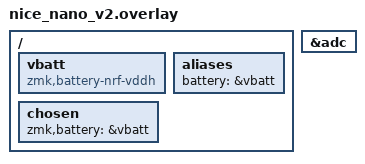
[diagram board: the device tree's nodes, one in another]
/* Enable SAADC and expose a ZMK battery device for nice!nano v2 */

&adc {
    status = "okay";
};

 / {
    vbatt: vbatt {
        /* Option A (preferred for nice!nano v2): */
        compatible = "zmk,battery-nrf-vddh";
        /* If link still fails, change the line above to:
         * compatible = "zmk,battery-nrf-vdd";
         */
        status = "okay";
    };

    /* Let ZMK find the device */
    aliases { battery = &vbatt; };

    chosen { zmk,battery = &vbatt; };
};
